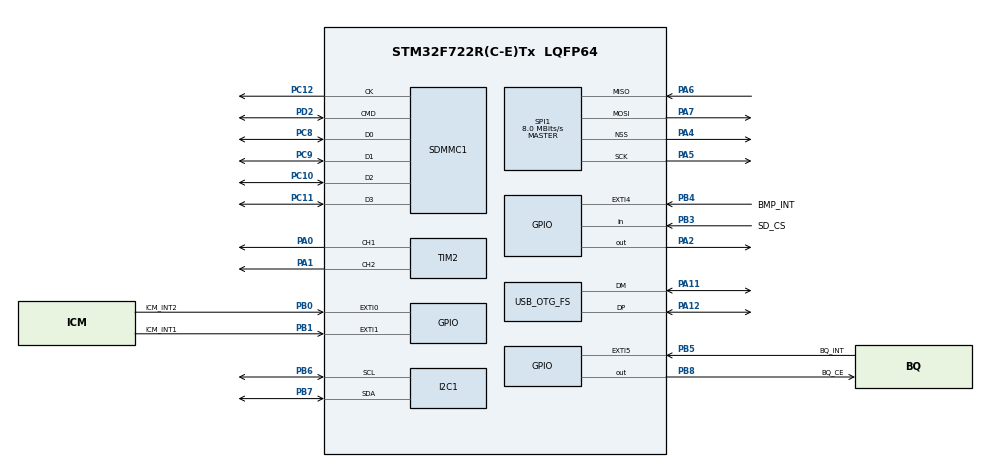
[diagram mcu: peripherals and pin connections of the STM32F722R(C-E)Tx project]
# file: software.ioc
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CORTEX_M7.default_mode_Activation=1
Mcu.Family=STM32F7
Mcu.Name=STM32F722R(C-E)Tx
Mcu.Package=LQFP64
NVIC.PriorityGroup=NVIC_PRIORITYGROUP_4
PA0-WKUP.Signal=S_TIM2_CH1_ETR
PA1.Signal=S_TIM2_CH2
PA11.Mode=Host_Only
PA11.Signal=USB_OTG_FS_DM
PA12.Mode=Host_Only
PA12.Signal=USB_OTG_FS_DP
PA2.Signal=GPIO_Output
PA4.Mode=NSS_Signal_Hard_Output
PA4.Signal=SPI1_NSS
PA5.Mode=Full_Duplex_Master
PA5.Signal=SPI1_SCK
PA6.Mode=Full_Duplex_Master
PA6.Signal=SPI1_MISO
PA7.Mode=Full_Duplex_Master
PA7.Signal=SPI1_MOSI
PB0.GPIO_Label=ICM_INT2
PB0.Signal=GPXTI0
PB1.GPIO_Label=ICM_INT1
PB1.Signal=GPXTI1
PB3.GPIO_Label=SD_CS
PB3.Signal=GPIO_Input
PB4.GPIO_Label=BMP_INT
PB4.Signal=GPXTI4
PB5.GPIO_Label=BQ_INT
PB5.Signal=GPXTI5
PB6.Mode=I2C
PB6.Signal=I2C1_SCL
PB7.Mode=I2C
PB7.Signal=I2C1_SDA
PB8.GPIO_Label=BQ_CE
PB8.Signal=GPIO_Output
PC10.Mode=SD_4_bits_Wide_bus
PC10.Signal=SDMMC1_D2
PC11.Mode=SD_4_bits_Wide_bus
PC11.Signal=SDMMC1_D3
PC12.Mode=SD_4_bits_Wide_bus
PC12.Signal=SDMMC1_CK
PC14-OSC32_IN.Mode=LSE-External-Oscillator
PC14-OSC32_IN.Signal=RCC_OSC32_IN
PC15-OSC32_OUT.Mode=LSE-External-Oscillator
PC15-OSC32_OUT.Signal=RCC_OSC32_OUT
PC8.Mode=SD_4_bits_Wide_bus
PC8.Signal=SDMMC1_D0
PC9.Mode=SD_4_bits_Wide_bus
PC9.Signal=SDMMC1_D1
PD2.Mode=SD_4_bits_Wide_bus
PD2.Signal=SDMMC1_CMD
PH0-OSC_IN.Mode=HSE-External-Oscillator
PH0-OSC_IN.Signal=RCC_OSC_IN
PH1-OSC_OUT.Mode=HSE-External-Oscillator
PH1-OSC_OUT.Signal=RCC_OSC_OUT
ProjectManager.HeapSize=0x200
ProjectManager.StackSize=0x400
ProjectManager.TargetToolchain=Makefile
RCC.HSE_VALUE=25000000
RCC.HSI_VALUE=16000000
RCC.PLLM=15
RCC.PLLN=144
RCC.PLLQ=5
RCC.USBFreq_Value=48000000
RCC.VCOOutputFreq_Value=240000000
SH.S_TIM2_CH1_ETR.0=TIM2_CH1,PWM Generation1 CH1
SH.S_TIM2_CH2.0=TIM2_CH2,PWM Generation2 CH2
SPI1.CalculateBaudRate=8.0 MBits/s
SPI1.Direction=SPI_DIRECTION_2LINES
SPI1.Mode=SPI_MODE_MASTER
SPI1.VirtualNSS=VM_NSSHARD
SPI1.VirtualType=VM_MASTER
TIM2.Channel-PWM\ Generation1\ CH1=TIM_CHANNEL_1
TIM2.Channel-PWM\ Generation2\ CH2=TIM_CHANNEL_2
USB_OTG_FS.VirtualMode=Host_Only
USB_OTG_FS.phy_itface=HCD_PHY_EMBEDDED
VP_TIM2_VS_ClockSourceINT.Mode=Internal
board=custom

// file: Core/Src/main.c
/* USER CODE BEGIN Header */
/**
  ******************************************************************************
  * @file           : main.c
  * @brief          : Main program body
  ******************************************************************************
  * @attention
  *
  * Copyright (c) 2025 STMicroelectronics.
  * All rights reserved.
  *
  * This software is licensed under terms that can be found in the LICENSE file
  * in the root directory of this software component.
  * If no LICENSE file comes with this software, it is provided AS-IS.
  *
  ******************************************************************************
  */
/* USER CODE END Header */
#include "main.h"

I2C_HandleTypeDef hi2c1;

SD_HandleTypeDef hsd1;

SPI_HandleTypeDef hspi1;

TIM_HandleTypeDef htim2;

HCD_HandleTypeDef hhcd_USB_OTG_FS;

void SystemClock_Config(void);
static void MPU_Config(void);
static void MX_GPIO_Init(void);
static void MX_I2C1_Init(void);
static void MX_SDMMC1_SD_Init(void);
static void MX_SPI1_Init(void);
static void MX_TIM2_Init(void);
static void MX_USB_OTG_FS_HCD_Init(void);

int main(void)
{

  /* MPU Configuration--------------------------------------------------------*/
  MPU_Config();

  /* MCU Configuration--------------------------------------------------------*/

  /* Reset of all peripherals, Initializes the Flash interface and the Systick. */
  HAL_Init();

  /* Configure the system clock */
  SystemClock_Config();

  /* Initialize all configured peripherals */
  MX_GPIO_Init();
  MX_I2C1_Init();
  MX_SDMMC1_SD_Init();
  MX_SPI1_Init();
  MX_TIM2_Init();
  MX_USB_OTG_FS_HCD_Init();
  /* USER CODE BEGIN 2 */

  HAL_TIM_PWM_Start(&htim2, TIM_CHANNEL_1);
  HAL_TIM_PWM_Start(&htim2, TIM_CHANNEL_2);
  HAL_I2C_Mem_Read(&hi2c1, 0x77 << 1, 0xD0, 1, &bmp_id, 1, HAL_MAX_DELAY);

  /* USER CODE END 2 */

  /* Infinite loop */
  /* USER CODE BEGIN WHILE */
  while (1)
  {
    // js flash on, off, 1s delay
//		HAL_GPIO_WritePin(GPIOA, GPIO_PIN_2, GPIO_PIN_SET); // LEDS ON
//		HAL_Delay(1000); // in ms
//		__HAL_TIM_SET_COMPARE(&htim2, TIM_CHANNEL_1, 1500);
//		__HAL_TIM_SET_COMPARE(&htim2, TIM_CHANNEL_2, 1500);
//		HAL_Delay(1000);
//		HAL_Delay(1000);

    HAL_I2C_Mem_Read(&hi2c1, 0x77 << 1, 0x04, 1, data, 3, HAL_MAX_DELAY);

    raw_pressure = ((uint32_t)data[0] << 16) |
                   ((uint32_t)data[1] << 8)  |
                   (uint32_t)data[2];

    if (raw_pressure > 50000) {
        HAL_GPIO_WritePin(GPIOA, GPIO_PIN_5, GPIO_PIN_SET);
    } else {
        HAL_GPIO_WritePin(GPIOA, GPIO_PIN_5, GPIO_PIN_RESET);
    }
    __HAL_TIM_SET_COMPARE(&htim2, TIM_CHANNEL_1, 1500);
    __HAL_TIM_SET_COMPARE(&htim2, TIM_CHANNEL_2, 1500);

    HAL_Delay(5000);

    /* USER CODE END WHILE */

  }
}

void SystemClock_Config(void)
{
  RCC_OscInitTypeDef RCC_OscInitStruct = {0};
  RCC_ClkInitTypeDef RCC_ClkInitStruct = {0};

  /** Configure LSE Drive Capability
  */
  HAL_PWR_EnableBkUpAccess();

  /** Configure the main internal regulator output voltage
  */
  __HAL_RCC_PWR_CLK_ENABLE();
  __HAL_PWR_VOLTAGESCALING_CONFIG(PWR_REGULATOR_VOLTAGE_SCALE3);

  /** Initializes the RCC Oscillators according to the specified parameters
  * in the RCC_OscInitTypeDef structure.
  */
  RCC_OscInitStruct.OscillatorType = RCC_OSCILLATORTYPE_HSI|RCC_OSCILLATORTYPE_HSE;
  RCC_OscInitStruct.HSEState = RCC_HSE_ON;
  RCC_OscInitStruct.HSIState = RCC_HSI_ON;
  RCC_OscInitStruct.HSICalibrationValue = RCC_HSICALIBRATION_DEFAULT;
  RCC_OscInitStruct.PLL.PLLState = RCC_PLL_ON;
  RCC_OscInitStruct.PLL.PLLSource = RCC_PLLSOURCE_HSE;
  RCC_OscInitStruct.PLL.PLLM = 15;
  RCC_OscInitStruct.PLL.PLLN = 144;
  RCC_OscInitStruct.PLL.PLLP = RCC_PLLP_DIV2;
  RCC_OscInitStruct.PLL.PLLQ = 5;
  if (HAL_RCC_OscConfig(&RCC_OscInitStruct) != HAL_OK)
  {
    Error_Handler();
  }

  /** Initializes the CPU, AHB and APB buses clocks
  */
  RCC_ClkInitStruct.ClockType = RCC_CLOCKTYPE_HCLK|RCC_CLOCKTYPE_SYSCLK
                              |RCC_CLOCKTYPE_PCLK1|RCC_CLOCKTYPE_PCLK2;
  RCC_ClkInitStruct.SYSCLKSource = RCC_SYSCLKSOURCE_HSI;
  RCC_ClkInitStruct.AHBCLKDivider = RCC_SYSCLK_DIV1;
  RCC_ClkInitStruct.APB1CLKDivider = RCC_HCLK_DIV1;
  RCC_ClkInitStruct.APB2CLKDivider = RCC_HCLK_DIV1;

  if (HAL_RCC_ClockConfig(&RCC_ClkInitStruct, FLASH_LATENCY_0) != HAL_OK)
  {
    Error_Handler();
  }
}

static void MX_I2C1_Init(void)
{

  hi2c1.Instance = I2C1;
  hi2c1.Init.Timing = 0x00303D5B;
  hi2c1.Init.OwnAddress1 = 0;
  hi2c1.Init.AddressingMode = I2C_ADDRESSINGMODE_7BIT;
  hi2c1.Init.DualAddressMode = I2C_DUALADDRESS_DISABLE;
  hi2c1.Init.OwnAddress2 = 0;
  hi2c1.Init.OwnAddress2Masks = I2C_OA2_NOMASK;
  hi2c1.Init.GeneralCallMode = I2C_GENERALCALL_DISABLE;
  hi2c1.Init.NoStretchMode = I2C_NOSTRETCH_DISABLE;
  if (HAL_I2C_Init(&hi2c1) != HAL_OK)
  {
    Error_Handler();
  }

  /** Configure Analogue filter
  */
  if (HAL_I2CEx_ConfigAnalogFilter(&hi2c1, I2C_ANALOGFILTER_ENABLE) != HAL_OK)
  {
    Error_Handler();
  }

  /** Configure Digital filter
  */
  if (HAL_I2CEx_ConfigDigitalFilter(&hi2c1, 0) != HAL_OK)
  {
    Error_Handler();
  }

}

static void MX_SDMMC1_SD_Init(void)
{

  hsd1.Instance = SDMMC1;
  hsd1.Init.ClockEdge = SDMMC_CLOCK_EDGE_RISING;
  hsd1.Init.ClockBypass = SDMMC_CLOCK_BYPASS_DISABLE;
  hsd1.Init.ClockPowerSave = SDMMC_CLOCK_POWER_SAVE_DISABLE;
  hsd1.Init.BusWide = SDMMC_BUS_WIDE_1B;
  hsd1.Init.HardwareFlowControl = SDMMC_HARDWARE_FLOW_CONTROL_DISABLE;
  hsd1.Init.ClockDiv = 0;
  if (HAL_SD_Init(&hsd1) != HAL_OK)
  {
    Error_Handler();
  }
  if (HAL_SD_ConfigWideBusOperation(&hsd1, SDMMC_BUS_WIDE_4B) != HAL_OK)
  {
    Error_Handler();
  }

}

static void MX_SPI1_Init(void)
{

  /* SPI1 parameter configuration*/
  hspi1.Instance = SPI1;
  hspi1.Init.Mode = SPI_MODE_MASTER;
  hspi1.Init.Direction = SPI_DIRECTION_2LINES;
  hspi1.Init.DataSize = SPI_DATASIZE_4BIT;
  hspi1.Init.CLKPolarity = SPI_POLARITY_LOW;
  hspi1.Init.CLKPhase = SPI_PHASE_1EDGE;
  hspi1.Init.NSS = SPI_NSS_HARD_OUTPUT;
  hspi1.Init.BaudRatePrescaler = SPI_BAUDRATEPRESCALER_2;
  hspi1.Init.FirstBit = SPI_FIRSTBIT_MSB;
  hspi1.Init.TIMode = SPI_TIMODE_DISABLE;
  hspi1.Init.CRCCalculation = SPI_CRCCALCULATION_DISABLE;
  hspi1.Init.CRCPolynomial = 7;
  hspi1.Init.CRCLength = SPI_CRC_LENGTH_DATASIZE;
  hspi1.Init.NSSPMode = SPI_NSS_PULSE_ENABLE;
  if (HAL_SPI_Init(&hspi1) != HAL_OK)
  {
    Error_Handler();
  }

}

static void MX_TIM2_Init(void)
{

  TIM_ClockConfigTypeDef sClockSourceConfig = {0};
  TIM_MasterConfigTypeDef sMasterConfig = {0};
  TIM_OC_InitTypeDef sConfigOC = {0};

  htim2.Instance = TIM2;
  htim2.Init.Prescaler = 0;
  htim2.Init.CounterMode = TIM_COUNTERMODE_UP;
  htim2.Init.Period = 4294967295;
  htim2.Init.ClockDivision = TIM_CLOCKDIVISION_DIV1;
  htim2.Init.AutoReloadPreload = TIM_AUTORELOAD_PRELOAD_DISABLE;
  if (HAL_TIM_Base_Init(&htim2) != HAL_OK)
  {
    Error_Handler();
  }
  sClockSourceConfig.ClockSource = TIM_CLOCKSOURCE_INTERNAL;
  if (HAL_TIM_ConfigClockSource(&htim2, &sClockSourceConfig) != HAL_OK)
  {
    Error_Handler();
  }
  if (HAL_TIM_PWM_Init(&htim2) != HAL_OK)
  {
    Error_Handler();
  }
  sMasterConfig.MasterOutputTrigger = TIM_TRGO_RESET;
  sMasterConfig.MasterSlaveMode = TIM_MASTERSLAVEMODE_DISABLE;
  if (HAL_TIMEx_MasterConfigSynchronization(&htim2, &sMasterConfig) != HAL_OK)
  {
    Error_Handler();
  }
  sConfigOC.OCMode = TIM_OCMODE_PWM1;
  sConfigOC.Pulse = 0;
  sConfigOC.OCPolarity = TIM_OCPOLARITY_HIGH;
  sConfigOC.OCFastMode = TIM_OCFAST_DISABLE;
  if (HAL_TIM_PWM_ConfigChannel(&htim2, &sConfigOC, TIM_CHANNEL_1) != HAL_OK)
  {
    Error_Handler();
  }
  if (HAL_TIM_PWM_ConfigChannel(&htim2, &sConfigOC, TIM_CHANNEL_2) != HAL_OK)
  {
    Error_Handler();
  }
  HAL_TIM_MspPostInit(&htim2);

}

static void MX_USB_OTG_FS_HCD_Init(void)
{

  hhcd_USB_OTG_FS.Instance = USB_OTG_FS;
  hhcd_USB_OTG_FS.Init.Host_channels = 12;
  hhcd_USB_OTG_FS.Init.speed = USB_OTG_SPEED_FULL;
  hhcd_USB_OTG_FS.Init.dma_enable = DISABLE;
  hhcd_USB_OTG_FS.Init.phy_itface = HCD_PHY_EMBEDDED;
  hhcd_USB_OTG_FS.Init.Sof_enable = DISABLE;
  hhcd_USB_OTG_FS.Init.vbus_sensing_enable = DISABLE;
  if (HAL_HCD_Init(&hhcd_USB_OTG_FS) != HAL_OK)
  {
    Error_Handler();
  }

}

static void MX_GPIO_Init(void)
{
  GPIO_InitTypeDef GPIO_InitStruct = {0};

  /* GPIO Ports Clock Enable */
  __HAL_RCC_GPIOC_CLK_ENABLE();
  __HAL_RCC_GPIOH_CLK_ENABLE();
  __HAL_RCC_GPIOA_CLK_ENABLE();
  __HAL_RCC_GPIOB_CLK_ENABLE();
  __HAL_RCC_GPIOD_CLK_ENABLE();

  /*Configure GPIO pin Output Level */
  HAL_GPIO_WritePin(GPIOA, GPIO_PIN_2, GPIO_PIN_RESET);

  /*Configure GPIO pin Output Level */
  HAL_GPIO_WritePin(BQ_CE_GPIO_Port, BQ_CE_Pin, GPIO_PIN_RESET);

  /*Configure GPIO pin : PA2 */
  GPIO_InitStruct.Pin = GPIO_PIN_2;
  GPIO_InitStruct.Mode = GPIO_MODE_OUTPUT_PP;
  GPIO_InitStruct.Pull = GPIO_NOPULL;
  GPIO_InitStruct.Speed = GPIO_SPEED_FREQ_LOW;
  HAL_GPIO_Init(GPIOA, &GPIO_InitStruct);

  /*Configure GPIO pins : ICM_INT2_Pin ICM_INT1_Pin BMP_INT_Pin BQ_INT_Pin */
  GPIO_InitStruct.Pin = ICM_INT2_Pin|ICM_INT1_Pin|BMP_INT_Pin|BQ_INT_Pin;
  GPIO_InitStruct.Mode = GPIO_MODE_IT_RISING;
  GPIO_InitStruct.Pull = GPIO_NOPULL;
  HAL_GPIO_Init(GPIOB, &GPIO_InitStruct);

  /*Configure GPIO pin : SD_CS_Pin */
  GPIO_InitStruct.Pin = SD_CS_Pin;
  GPIO_InitStruct.Mode = GPIO_MODE_INPUT;
  GPIO_InitStruct.Pull = GPIO_NOPULL;
  HAL_GPIO_Init(SD_CS_GPIO_Port, &GPIO_InitStruct);

  /*Configure GPIO pin : BQ_CE_Pin */
  GPIO_InitStruct.Pin = BQ_CE_Pin;
  GPIO_InitStruct.Mode = GPIO_MODE_OUTPUT_PP;
  GPIO_InitStruct.Pull = GPIO_NOPULL;
  GPIO_InitStruct.Speed = GPIO_SPEED_FREQ_LOW;
  HAL_GPIO_Init(BQ_CE_GPIO_Port, &GPIO_InitStruct);

}

 /* MPU Configuration */

void MPU_Config(void)
{
  MPU_Region_InitTypeDef MPU_InitStruct = {0};

  /* Disables the MPU */
  HAL_MPU_Disable();

  /** Initializes and configures the Region and the memory to be protected
  */
  MPU_InitStruct.Enable = MPU_REGION_ENABLE;
  MPU_InitStruct.Number = MPU_REGION_NUMBER0;
  MPU_InitStruct.BaseAddress = 0x0;
  MPU_InitStruct.Size = MPU_REGION_SIZE_4GB;
  MPU_InitStruct.SubRegionDisable = 0x87;
  MPU_InitStruct.TypeExtField = MPU_TEX_LEVEL0;
  MPU_InitStruct.AccessPermission = MPU_REGION_NO_ACCESS;
  MPU_InitStruct.DisableExec = MPU_INSTRUCTION_ACCESS_DISABLE;
  MPU_InitStruct.IsShareable = MPU_ACCESS_SHAREABLE;
  MPU_InitStruct.IsCacheable = MPU_ACCESS_NOT_CACHEABLE;
  MPU_InitStruct.IsBufferable = MPU_ACCESS_NOT_BUFFERABLE;

  HAL_MPU_ConfigRegion(&MPU_InitStruct);
  /* Enables the MPU */
  HAL_MPU_Enable(MPU_PRIVILEGED_DEFAULT);

}

void Error_Handler(void)
{
  __disable_irq();
  while (1)
  {
  }
}
